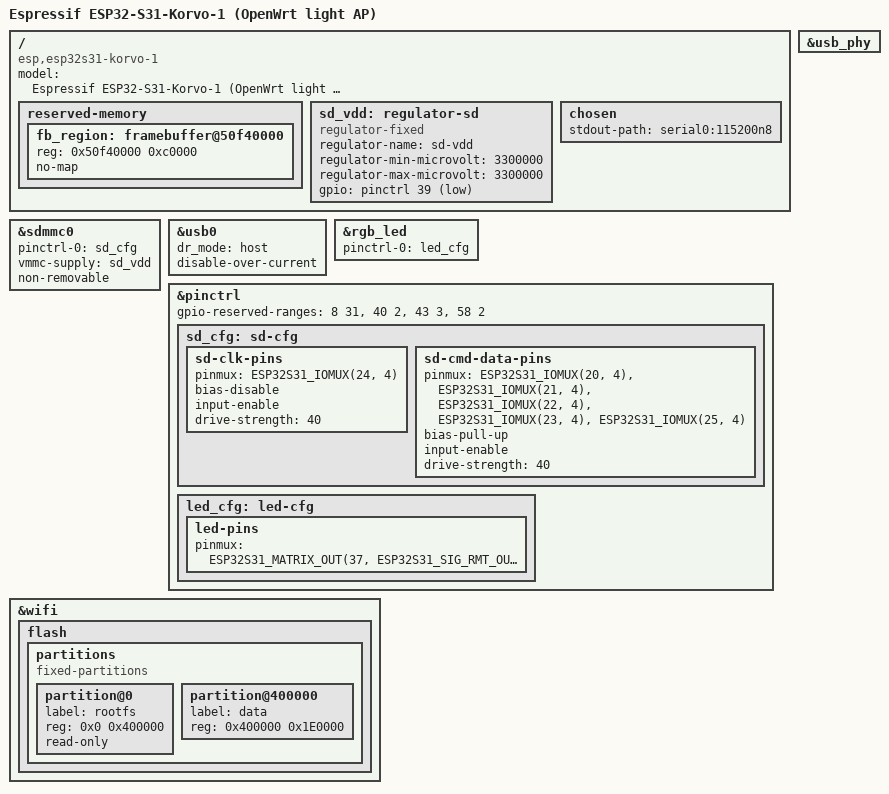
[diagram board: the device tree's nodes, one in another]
// SPDX-License-Identifier: GPL-2.0+
/*
 * ESP32-S31-Korvo-1, OpenWrt light-AP variant.
 *
 * Differences from esp32s31_korvo1.dts:
 *  - The GT1151 touchscreen child is dropped (the OpenWrt kernel has
 *    no input/touch drivers) and i2c0 stays disabled.
 *  - usb0 stays at high-speed: forcing full-speed here once coincided
 *    with a boot problem that later turned out to be unrelated (the
 *    CONFIG_BT drop killing ESP32S31_HOSTED); never re-tested after the
 *    real fix, so FS remains unproven.  HS is known good.
 *
 * The framebuffer reservation (768 KiB at 0x50f40000) is kept even
 * though the headless firmware never renders: merging that window into
 * the general pool breaks userspace.  With the reservation removed the
 * kernel boots, but PID 1 dies jumping through a wild libgcc_s pointer
 * (instruction access fault, badaddr == PC in an unmapped region, cause
 * 1) — the window must still be special in the early MMU/PMA setup
 * (the original DTS notes OpenSBI maps it uncached with two PMA
 * entries; the kernel side likely has a matching hardcoded assumption).
 * Stopping the loader's LCDC DMA at handoff did not help.  Not worth
 * chasing for 768 KiB of 16 MiB.
 */
/dts-v1/;
#include "esp32s31.dtsi"
#include <dt-bindings/gpio/gpio.h>

/ {
	model = "Espressif ESP32-S31-Korvo-1 (OpenWrt light AP)";
	compatible = "esp,esp32s31-korvo-1", "esp,esp32s31";

	reserved-memory {
		#address-cells = <1>;
		#size-cells = <1>;
		ranges;

		/* Same reservation as the desktop line; see the header. */
		fb_region: framebuffer@50f40000 {
			reg = <0x50f40000 0xc0000>;
			no-map;
		};
	};

	/* GPIO39 low switches the power of the microSD slot on. */
	sd_vdd: regulator-sd {
		compatible = "regulator-fixed";
		regulator-name = "sd-vdd";
		regulator-min-microvolt = <3300000>;
		regulator-max-microvolt = <3300000>;
		gpio = <&pinctrl 39 GPIO_ACTIVE_LOW>;
	};

	chosen {
		stdout-path = "serial0:115200n8";
	};
};

/* The slot has no card-detect or write-protect contact. */
&sdmmc0 {
	pinctrl-names = "default";
	pinctrl-0 = <&sd_cfg>;
	vmmc-supply = <&sd_vdd>;
	non-removable;
	status = "okay";
};

/* The Type-A port: host only, with a TPS2051C switch for VBUS. */
&usb_phy { status = "okay"; };

&usb0 {
	dr_mode = "host";
	disable-over-current;
	/*
	 * 2026-10-24: full-speed here once "coincided" with a reset loop,
	 * but the loop's real cause was the slim kernel dropping CONFIG_BT
	 * (which silently erases CONFIG_ESP32S31_HOSTED -> no MTD -> no
	 * /dev/mtdblock0 -> flash-init reboots).  FS was never retried
	 * after that fix; HS is known good and stays.
	 */
	status = "okay";
};

/* WS2812 RGB LED on GPIO37. */
&rgb_led {
	pinctrl-names = "default";
	pinctrl-0 = <&led_cfg>;
	status = "okay";
};

/*
 * The loader drives the LCD (GPIO8-19, 33-36, 38, 40, 43-45).  The card pins
 * (GPIO20-25) and the LED (GPIO37) belong to drivers.  With the flash, GPIO41
 * and UART0, Linux must not use them as GPIOs.  GPIO39 is the card power.
 */
&pinctrl {
	gpio-reserved-ranges = <8 31>, <40 2>, <43 3>, <58 2>;

	/* The SD host on its IO MUX pins, function 4 */
	sd_cfg: sd-cfg {
		sd-clk-pins {
			pinmux = <ESP32S31_IOMUX(24, 4)>;
			bias-disable;
			input-enable;
			drive-strength = <40>;
		};

		sd-cmd-data-pins {
			pinmux = <ESP32S31_IOMUX(20, 4)>,	/* D0 */
				 <ESP32S31_IOMUX(21, 4)>,	/* D1 */
				 <ESP32S31_IOMUX(22, 4)>,	/* D2 */
				 <ESP32S31_IOMUX(23, 4)>,	/* D3 */
				 <ESP32S31_IOMUX(25, 4)>;	/* CMD */
			bias-pull-up;
			input-enable;
			drive-strength = <40>;
		};
	};

	led_cfg: led-cfg {
		led-pins {
			pinmux = <ESP32S31_MATRIX_OUT(37, ESP32S31_SIG_RMT_OUT0)>;
		};
	};
};

/*
 * OpenWrt flash firmware: "rootfs" (squashfs, ro) and "data"
 * from bootloader/partitions-korvo1.csv, from the start of rootfs.
 */
&wifi {
	flash {
		partitions {
			compatible = "fixed-partitions";
			#address-cells = <1>;
			#size-cells = <1>;

			partition@0 {
				label = "rootfs";
				reg = <0x0 0x400000>;
				read-only;
			};

			partition@400000 {
				label = "data";
				reg = <0x400000 0x1E0000>;
			};
		};
	};
};
